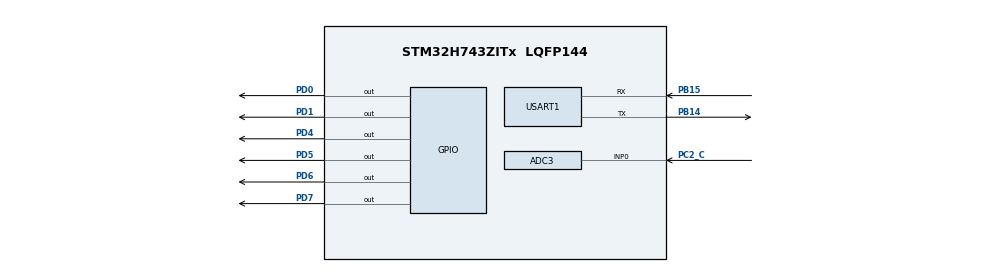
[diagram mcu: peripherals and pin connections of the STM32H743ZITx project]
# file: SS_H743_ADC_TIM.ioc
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ADC3.Channel-0\#ChannelRegularConversion=ADC_CHANNEL_0
ADC3.ClockPrescaler=ADC_CLOCK_ASYNC_DIV1
ADC3.NbrOfConversionFlag=1
ADC3.OffsetNumber-0\#ChannelRegularConversion=ADC_OFFSET_NONE
ADC3.Rank-0\#ChannelRegularConversion=1
ADC3.SamplingTime-0\#ChannelRegularConversion=ADC_SAMPLETIME_387CYCLES_5
Mcu.Family=STM32H7
Mcu.Name=STM32H743ZITx
Mcu.Package=LQFP144
NVIC.PriorityGroup=NVIC_PRIORITYGROUP_4
NVIC.TIM1_BRK_IRQn=true\:0\:0\:false\:false\:true\:true\:true
NVIC.TIM1_CC_IRQn=true\:0\:0\:false\:false\:true\:true\:true
NVIC.TIM1_TRG_COM_IRQn=true\:0\:0\:false\:false\:true\:true\:true
NVIC.TIM1_UP_IRQn=true\:0\:0\:false\:false\:true\:true\:true
NVIC.USART1_IRQn=true\:0\:0\:false\:false\:true\:true\:true
PB14.Mode=Asynchronous
PB14.Signal=USART1_TX
PB15.Mode=Asynchronous
PB15.Signal=USART1_RX
PC2_C.Mode=IN0-Single-Ended
PC2_C.Signal=ADC3_INP0
PD0.Signal=GPIO_Output
PD1.Signal=GPIO_Output
PD4.Signal=GPIO_Output
PD5.Signal=GPIO_Output
PD6.Signal=GPIO_Output
PD7.Signal=GPIO_Output
PH0-OSC_IN\ (PH0).Mode=HSE-External-Oscillator
PH0-OSC_IN\ (PH0).Signal=RCC_OSC_IN
PH1-OSC_OUT\ (PH1).Mode=HSE-External-Oscillator
PH1-OSC_OUT\ (PH1).Signal=RCC_OSC_OUT
ProjectManager.HeapSize=0x200
ProjectManager.StackSize=0x400
ProjectManager.TargetToolchain=MDK-ARM V5.27
RCC.ADCFreq_Value=15000000
RCC.APB1Freq_Value=64000000
RCC.APB2Freq_Value=64000000
RCC.APB3Freq_Value=64000000
RCC.APB4Freq_Value=64000000
RCC.CortexFreq_Value=128000000
RCC.D1CPRE=RCC_SYSCLK_DIV2
RCC.D1PPRE=RCC_APB3_DIV2
RCC.D2PPRE1=RCC_APB1_DIV2
RCC.D2PPRE2=RCC_APB2_DIV2
RCC.D3PPRE=RCC_APB4_DIV2
RCC.DIVM1=4
RCC.DIVM2=4
RCC.DIVN1=32
RCC.DIVN2=9
RCC.DIVP2=10
RCC.HCLKFreq_Value=128000000
RCC.PLL2FRACN=3072
RCC.PLL3FRACN=0
RCC.PLLFRACN=0
RCC.SYSCLKFreq_VALUE=256000000
RCC.SYSCLKSource=RCC_SYSCLKSOURCE_PLLCLK
RCC.USBFreq_Value=256000000
TIM1.Period=5-1
TIM1.Prescaler=900-1
TIM2.Period=100-1
TIM2.Prescaler=1280-1
USART1.VirtualMode-Asynchronous=VM_ASYNC
VP_TIM1_VS_ClockSourceINT.Mode=Internal
VP_TIM2_VS_ClockSourceINT.Mode=Internal
board=custom

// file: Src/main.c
/* USER CODE BEGIN Header */
/**
  ******************************************************************************
  * @file           : main.c
  * @brief          : Main program body
  ******************************************************************************
  * @attention
  *
  * <h2><center>&copy; Copyright (c) 2020 STMicroelectronics.
  * All rights reserved.</center></h2>
  *
  * This software component is licensed by ST under BSD 3-Clause license,
  * the "License"; You may not use this file except in compliance with the
  * License. You may obtain a copy of the License at:
  *                        opensource.org/licenses/BSD-3-Clause
  *
  ******************************************************************************
  */
/* USER CODE END Header */

#include "main.h"
#include "adc.h"
#include "tim.h"
#include "usart.h"
#include "gpio.h"

/* USER CODE BEGIN Includes */
#include "stdio.h"
#include "MF_FFT.h"
#include "MF_TIMADC.h"
#include "arm_math.h"
#include "MF_HMI.h"
//测未知频率的基波的THD，比如方波=43.4，三角波=12.8
/* USER CODE END Includes */

void SystemClock_Config(void);

int main(void)
{
  /* USER CODE BEGIN 1 */
//int i ;
//	double temp = 0 ;
//	uint32_t rx[3]={0};
//	float temp ;
  /* USER CODE END 1 */

  /* MCU Configuration--------------------------------------------------------*/

  /* Reset of all peripherals, Initializes the Flash interface and the Systick. */
  HAL_Init();

  /* Configure the system clock */
  SystemClock_Config();

  /* Initialize all configured peripherals */
  MX_GPIO_Init();
  MX_ADC3_Init();
  MX_TIM1_Init();
  MX_USART1_UART_Init();
  MX_TIM2_Init();
  /* USER CODE BEGIN 2 */

//	HAL_GPIO_WritePin(GPIOD,GPIO_PIN_0,GPIO_PIN_RESET);
// 1 0 0 0 ===> 无明显失真的正弦波
	MF_Control_GPIO( GPIO_PIN_SET , GPIO_PIN_RESET , GPIO_PIN_RESET , GPIO_PIN_RESET);

	receiveKey = 0 ;
	HAL_UART_Receive_IT(&huart1,&receiveKey,1);
//	HAL_TIM_Base_Start_IT(&htim1);
  /* USER CODE END 2 */

  /* Infinite loop */
  /* USER CODE BEGIN WHILE */
  while (1)
  {

		witchKey();
//		MF_SignalInput();
//		MF_FFT_MagOperation();
//
//		for(i=0;i<Length_Of_FFT;i++){
//			printf("%d ===> %.3f\r\n",i,MF_FFT_Outputbuff[i]);
//		}
//		printf("\r\n");

    /* USER CODE END WHILE */

  }
}

void SystemClock_Config(void)
{
  RCC_OscInitTypeDef RCC_OscInitStruct = {0};
  RCC_ClkInitTypeDef RCC_ClkInitStruct = {0};
  RCC_PeriphCLKInitTypeDef PeriphClkInitStruct = {0};

  /** Supply configuration update enable
  */
  HAL_PWREx_ConfigSupply(PWR_LDO_SUPPLY);
  /** Configure the main internal regulator output voltage
  */
  __HAL_PWR_VOLTAGESCALING_CONFIG(PWR_REGULATOR_VOLTAGE_SCALE2);

  while(!__HAL_PWR_GET_FLAG(PWR_FLAG_VOSRDY)) {}
  /** Macro to configure the PLL clock source
  */
  __HAL_RCC_PLL_PLLSOURCE_CONFIG(RCC_PLLSOURCE_HSI);
  /** Initializes the CPU, AHB and APB busses clocks
  */
  RCC_OscInitStruct.OscillatorType = RCC_OSCILLATORTYPE_HSI;
  RCC_OscInitStruct.HSIState = RCC_HSI_DIV1;
  RCC_OscInitStruct.HSICalibrationValue = RCC_HSICALIBRATION_DEFAULT;
  RCC_OscInitStruct.PLL.PLLState = RCC_PLL_ON;
  RCC_OscInitStruct.PLL.PLLSource = RCC_PLLSOURCE_HSI;
  RCC_OscInitStruct.PLL.PLLM = 4;
  RCC_OscInitStruct.PLL.PLLN = 32;
  RCC_OscInitStruct.PLL.PLLP = 2;
  RCC_OscInitStruct.PLL.PLLQ = 2;
  RCC_OscInitStruct.PLL.PLLR = 2;
  RCC_OscInitStruct.PLL.PLLRGE = RCC_PLL1VCIRANGE_3;
  RCC_OscInitStruct.PLL.PLLVCOSEL = RCC_PLL1VCOWIDE;
  RCC_OscInitStruct.PLL.PLLFRACN = 0;
  if (HAL_RCC_OscConfig(&RCC_OscInitStruct) != HAL_OK)
  {
    Error_Handler();
  }
  /** Initializes the CPU, AHB and APB busses clocks
  */
  RCC_ClkInitStruct.ClockType = RCC_CLOCKTYPE_HCLK|RCC_CLOCKTYPE_SYSCLK
                              |RCC_CLOCKTYPE_PCLK1|RCC_CLOCKTYPE_PCLK2
                              |RCC_CLOCKTYPE_D3PCLK1|RCC_CLOCKTYPE_D1PCLK1;
  RCC_ClkInitStruct.SYSCLKSource = RCC_SYSCLKSOURCE_PLLCLK;
  RCC_ClkInitStruct.SYSCLKDivider = RCC_SYSCLK_DIV2;
  RCC_ClkInitStruct.AHBCLKDivider = RCC_HCLK_DIV1;
  RCC_ClkInitStruct.APB3CLKDivider = RCC_APB3_DIV2;
  RCC_ClkInitStruct.APB1CLKDivider = RCC_APB1_DIV2;
  RCC_ClkInitStruct.APB2CLKDivider = RCC_APB2_DIV2;
  RCC_ClkInitStruct.APB4CLKDivider = RCC_APB4_DIV2;

  if (HAL_RCC_ClockConfig(&RCC_ClkInitStruct, FLASH_LATENCY_1) != HAL_OK)
  {
    Error_Handler();
  }
  PeriphClkInitStruct.PeriphClockSelection = RCC_PERIPHCLK_USART1|RCC_PERIPHCLK_ADC;
  PeriphClkInitStruct.PLL2.PLL2M = 4;
  PeriphClkInitStruct.PLL2.PLL2N = 9;
  PeriphClkInitStruct.PLL2.PLL2P = 10;
  PeriphClkInitStruct.PLL2.PLL2Q = 2;
  PeriphClkInitStruct.PLL2.PLL2R = 2;
  PeriphClkInitStruct.PLL2.PLL2RGE = RCC_PLL2VCIRANGE_3;
  PeriphClkInitStruct.PLL2.PLL2VCOSEL = RCC_PLL2VCOMEDIUM;
  PeriphClkInitStruct.PLL2.PLL2FRACN = 3072;
  PeriphClkInitStruct.Usart16ClockSelection = RCC_USART16CLKSOURCE_D2PCLK2;
  PeriphClkInitStruct.AdcClockSelection = RCC_ADCCLKSOURCE_PLL2;
  if (HAL_RCCEx_PeriphCLKConfig(&PeriphClkInitStruct) != HAL_OK)
  {
    Error_Handler();
  }
}

void Error_Handler(void)
{
}

/************************ (C) COPYRIGHT STMicroelectronics *****END OF FILE****/
